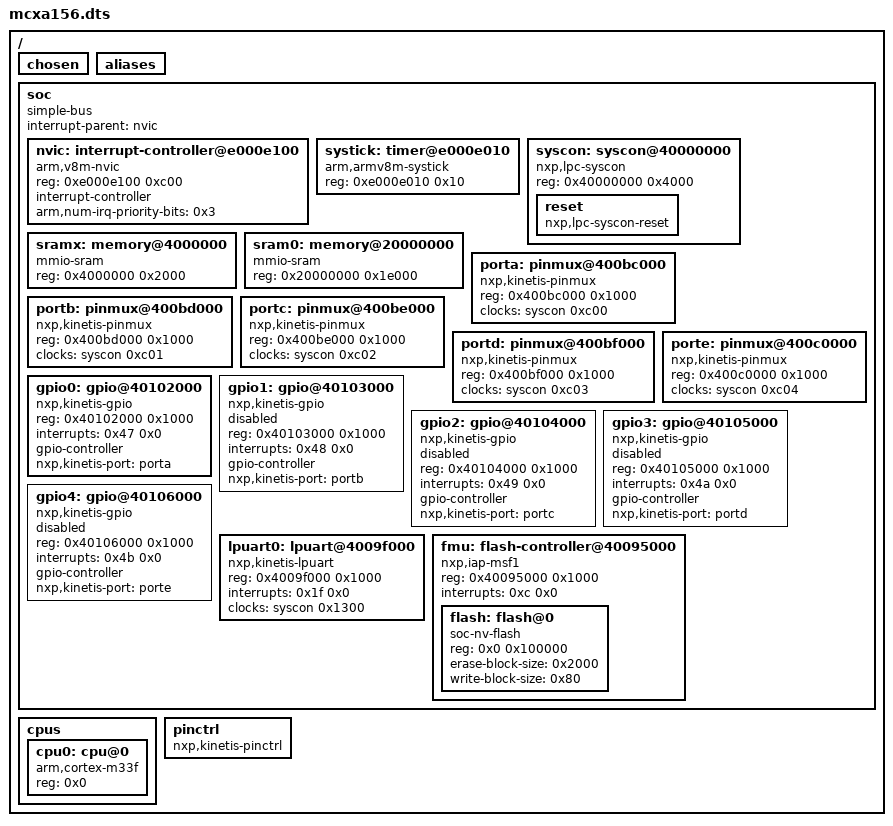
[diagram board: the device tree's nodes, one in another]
/dts-v1/;

/ {
	#address-cells = < 0x1 >;
	#size-cells = < 0x1 >;
	chosen {
	};
	aliases {
	};
	soc {
		#address-cells = < 0x1 >;
		#size-cells = < 0x1 >;
		compatible = "simple-bus";
		interrupt-parent = < &nvic >;
		ranges;
		nvic: interrupt-controller@e000e100 {
			#address-cells = < 0x1 >;
			compatible = "arm,v8m-nvic";
			reg = < 0xe000e100 0xc00 >;
			interrupt-controller;
			#interrupt-cells = < 0x2 >;
			arm,num-irq-priority-bits = < 0x3 >;
			phandle = < 0x1 >;
		};
		systick: timer@e000e010 {
			compatible = "arm,armv8m-systick";
			reg = < 0xe000e010 0x10 >;
		};
		syscon: syscon@40000000 {
			compatible = "nxp,lpc-syscon";
			reg = < 0x40000000 0x4000 >;
			#clock-cells = < 0x1 >;
			phandle = < 0x2 >;
			reset: reset {
				compatible = "nxp,lpc-syscon-reset";
				#reset-cells = < 0x1 >;
			};
		};
		sramx: memory@4000000 {
			compatible = "mmio-sram";
			reg = < 0x4000000 0x2000 >;
		};
		sram0: memory@20000000 {
			compatible = "mmio-sram";
			reg = < 0x20000000 0x1e000 >;
		};
		porta: pinmux@400bc000 {
			compatible = "nxp,kinetis-pinmux";
			reg = < 0x400bc000 0x1000 >;
			clocks = < &syscon 0xc00 >;
			phandle = < 0x3 >;
		};
		portb: pinmux@400bd000 {
			compatible = "nxp,kinetis-pinmux";
			reg = < 0x400bd000 0x1000 >;
			clocks = < &syscon 0xc01 >;
			phandle = < 0x4 >;
		};
		portc: pinmux@400be000 {
			compatible = "nxp,kinetis-pinmux";
			reg = < 0x400be000 0x1000 >;
			clocks = < &syscon 0xc02 >;
			phandle = < 0x5 >;
		};
		portd: pinmux@400bf000 {
			compatible = "nxp,kinetis-pinmux";
			reg = < 0x400bf000 0x1000 >;
			clocks = < &syscon 0xc03 >;
			phandle = < 0x6 >;
		};
		porte: pinmux@400c0000 {
			compatible = "nxp,kinetis-pinmux";
			reg = < 0x400c0000 0x1000 >;
			clocks = < &syscon 0xc04 >;
			phandle = < 0x7 >;
		};
		gpio0: gpio@40102000 {
			compatible = "nxp,kinetis-gpio";
			reg = < 0x40102000 0x1000 >;
			interrupts = < 0x47 0x0 >;
			gpio-controller;
			#gpio-cells = < 0x2 >;
			nxp,kinetis-port = < &porta >;
		};
		gpio1: gpio@40103000 {
			compatible = "nxp,kinetis-gpio";
			status = "disabled";
			reg = < 0x40103000 0x1000 >;
			interrupts = < 0x48 0x0 >;
			gpio-controller;
			#gpio-cells = < 0x2 >;
			nxp,kinetis-port = < &portb >;
		};
		gpio2: gpio@40104000 {
			compatible = "nxp,kinetis-gpio";
			status = "disabled";
			reg = < 0x40104000 0x1000 >;
			interrupts = < 0x49 0x0 >;
			gpio-controller;
			#gpio-cells = < 0x2 >;
			nxp,kinetis-port = < &portc >;
		};
		gpio3: gpio@40105000 {
			compatible = "nxp,kinetis-gpio";
			status = "disabled";
			reg = < 0x40105000 0x1000 >;
			interrupts = < 0x4a 0x0 >;
			gpio-controller;
			#gpio-cells = < 0x2 >;
			nxp,kinetis-port = < &portd >;
		};
		gpio4: gpio@40106000 {
			compatible = "nxp,kinetis-gpio";
			status = "disabled";
			reg = < 0x40106000 0x1000 >;
			interrupts = < 0x4b 0x0 >;
			gpio-controller;
			#gpio-cells = < 0x2 >;
			nxp,kinetis-port = < &porte >;
		};
		lpuart0: lpuart@4009f000 {
			compatible = "nxp,kinetis-lpuart";
			reg = < 0x4009f000 0x1000 >;
			interrupts = < 0x1f 0x0 >;
			clocks = < &syscon 0x1300 >;
		};
		fmu: flash-controller@40095000 {
			compatible = "nxp,iap-msf1";
			reg = < 0x40095000 0x1000 >;
			interrupts = < 0xc 0x0 >;
			#address-cells = < 0x1 >;
			#size-cells = < 0x1 >;
			flash: flash@0 {
				compatible = "soc-nv-flash";
				reg = < 0x0 0x100000 >;
				erase-block-size = < 0x2000 >;
				write-block-size = < 0x80 >;
			};
		};
	};
	cpus {
		#address-cells = < 0x1 >;
		#size-cells = < 0x0 >;
		cpu0: cpu@0 {
			compatible = "arm,cortex-m33f";
			reg = < 0x0 >;
			#address-cells = < 0x1 >;
			#size-cells = < 0x1 >;
		};
	};
	pinctrl: pinctrl {
		compatible = "nxp,kinetis-pinctrl";
		status = "okay";
	};
};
